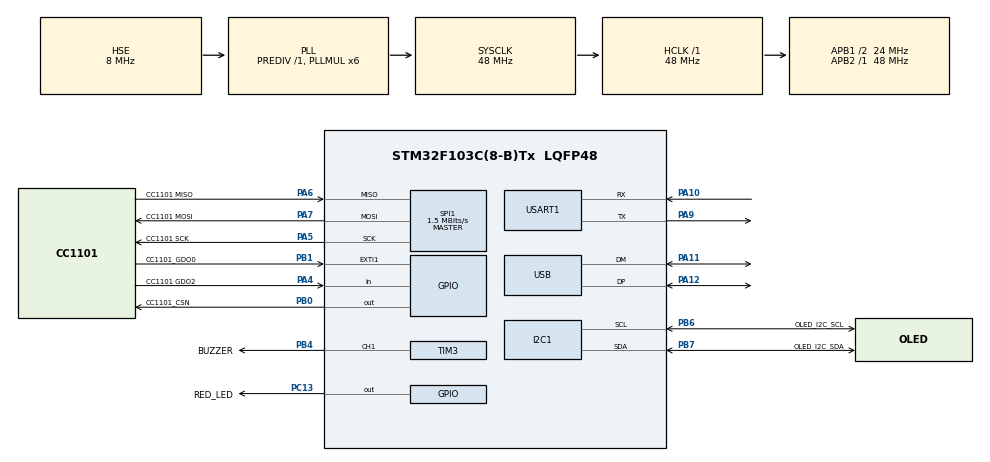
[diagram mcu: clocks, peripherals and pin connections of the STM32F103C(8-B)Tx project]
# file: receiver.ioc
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Dma.I2C1_TX.0.Direction=DMA_MEMORY_TO_PERIPH
Dma.I2C1_TX.0.Instance=DMA1_Channel6
Dma.I2C1_TX.0.MemDataAlignment=DMA_MDATAALIGN_BYTE
Dma.I2C1_TX.0.MemInc=DMA_MINC_ENABLE
Dma.I2C1_TX.0.Mode=DMA_NORMAL
Dma.I2C1_TX.0.PeriphDataAlignment=DMA_PDATAALIGN_BYTE
Dma.I2C1_TX.0.PeriphInc=DMA_PINC_DISABLE
Dma.I2C1_TX.0.Priority=DMA_PRIORITY_LOW
Dma.Request0=I2C1_TX
FREERTOS.INCLUDE_xTaskGetCurrentTaskHandle=1
FREERTOS.Tasks01=defaultTask,0,128,StartDefaultTask,Default,NULL
FREERTOS.configTIMER_QUEUE_LENGTH=10
FREERTOS.configTIMER_TASK_PRIORITY=2
FREERTOS.configTIMER_TASK_STACK_DEPTH=256
FREERTOS.configTOTAL_HEAP_SIZE=8192
FREERTOS.configUSE_IDLE_HOOK=1
FREERTOS.configUSE_TIMERS=1
I2C1.I2C_Mode=I2C_Fast
IWDG.Prescaler=IWDG_PRESCALER_8
Mcu.Family=STM32F1
Mcu.Name=STM32F103C(8-B)Tx
Mcu.Package=LQFP48
NVIC.DMA1_Channel6_IRQn=true\:5\:0\:false\:false\:true\:true\:true
NVIC.EXTI1_IRQn=true\:5\:0\:false\:false\:true\:true\:true
NVIC.I2C1_EV_IRQn=true\:5\:0\:false\:false\:true\:true\:true
NVIC.PriorityGroup=NVIC_PRIORITYGROUP_4
NVIC.TIM1_UP_IRQn=true\:0\:0\:false\:false\:true\:false\:true
NVIC.TimeBase=TIM1_UP_IRQn
NVIC.TimeBaseIP=TIM1
NVIC.USB_LP_CAN1_RX0_IRQn=true\:5\:0\:false\:false\:true\:true\:true
PA10.Mode=Asynchronous
PA10.Signal=USART1_RX
PA11.Mode=Device
PA11.Signal=USB_DM
PA12.Mode=Device
PA12.Signal=USB_DP
PA13.Mode=Serial_Wire
PA13.Signal=SYS_JTMS-SWDIO
PA14.Mode=Serial_Wire
PA14.Signal=SYS_JTCK-SWCLK
PA4.GPIO_Label=CC1101 GDO2
PA4.Signal=GPIO_Input
PA5.GPIO_Label=CC1101 SCK
PA5.Mode=Full_Duplex_Master
PA5.Signal=SPI1_SCK
PA6.GPIO_Label=CC1101 MISO
PA6.Mode=Full_Duplex_Master
PA6.Signal=SPI1_MISO
PA7.GPIO_Label=CC1101 MOSI
PA7.Mode=Full_Duplex_Master
PA7.Signal=SPI1_MOSI
PA9.Mode=Asynchronous
PA9.Signal=USART1_TX
PB0.GPIO_Label=CC1101_CSN
PB0.Signal=GPIO_Output
PB1.GPIO_Label=CC1101_GDO0
PB1.GPIO_ModeDefaultEXTI=GPIO_MODE_IT_FALLING
PB1.GPIO_PuPd=GPIO_NOPULL
PB1.Signal=GPXTI1
PB4.GPIO_Label=BUZZER
PB4.Signal=S_TIM3_CH1
PB6.GPIO_Label=OLED_I2C_SCL
PB6.Mode=I2C
PB6.Signal=I2C1_SCL
PB7.GPIO_Label=OLED_I2C_SDA
PB7.Mode=I2C
PB7.Signal=I2C1_SDA
PC13-TAMPER-RTC.GPIO_Label=RED_LED
PC13-TAMPER-RTC.Signal=GPIO_Output
PD0-OSC_IN.Mode=HSE-External-Oscillator
PD0-OSC_IN.Signal=RCC_OSC_IN
PD1-OSC_OUT.Mode=HSE-External-Oscillator
PD1-OSC_OUT.Signal=RCC_OSC_OUT
ProjectManager.HeapSize=0x200
ProjectManager.StackSize=0x400
ProjectManager.TargetToolchain=Makefile
RCC.ADCPresc=RCC_ADCPCLK2_DIV4
RCC.AHBFreq_Value=48000000
RCC.APB1CLKDivider=RCC_HCLK_DIV2
RCC.APB1Freq_Value=24000000
RCC.APB1TimFreq_Value=48000000
RCC.APB2Freq_Value=48000000
RCC.APB2TimFreq_Value=48000000
RCC.HCLKFreq_Value=48000000
RCC.PLLMUL=RCC_PLL_MUL6
RCC.SYSCLKFreq_VALUE=48000000
RCC.SYSCLKSource=RCC_SYSCLKSOURCE_PLLCLK
RCC.USBFreq_Value=48000000
SH.S_TIM3_CH1.0=TIM3_CH1,PWM Generation1 CH1
SPI1.BaudRatePrescaler=SPI_BAUDRATEPRESCALER_32
SPI1.CalculateBaudRate=1.5 MBits/s
SPI1.Direction=SPI_DIRECTION_2LINES
SPI1.Mode=SPI_MODE_MASTER
SPI1.VirtualType=VM_MASTER
TIM3.AutoReloadPreload=TIM_AUTORELOAD_PRELOAD_ENABLE
TIM3.Channel-PWM\ Generation1\ CH1=TIM_CHANNEL_1
TIM3.OCPolarity_1=TIM_OCPOLARITY_LOW
TIM3.Period=1024
TIM3.Prescaler=32
TIM3.Pulse-PWM\ Generation1\ CH1=512
USART1.VirtualMode=VM_ASYNC
USB_DEVICE.CLASS_NAME_FS=CDC
USB_DEVICE.VirtualMode=Cdc
USB_DEVICE.VirtualModeFS=Cdc_FS
VP_CRC_VS_CRC.Mode=CRC_Activate
VP_FREERTOS_VS_ENABLE.Mode=Enabled
VP_IWDG_VS_IWDG.Mode=IWDG_Activate
VP_SYS_VS_tim1.Mode=TIM1
VP_USB_DEVICE_VS_USB_DEVICE_CDC_FS.Mode=CDC_FS
board=receiver

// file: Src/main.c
/**
  ******************************************************************************
  * @file           : main.c
  * @brief          : Main program body
  ******************************************************************************
  * This notice applies to any and all portions of this file
  * that are not between comment pairs USER CODE BEGIN and
  * USER CODE END. Other portions of this file, whether
  * inserted by the user or by software development tools
  * are owned by their respective copyright owners.
  *
  * Copyright (c) 2018 STMicroelectronics International N.V.
  * All rights reserved.
  *
  * Redistribution and use in source and binary forms, with or without
  * modification, are permitted, provided that the following conditions are met:
  *
  * 1. Redistribution of source code must retain the above copyright notice,
  *    this list of conditions and the following disclaimer.
  * 2. Redistributions in binary form must reproduce the above copyright notice,
  *    this list of conditions and the following disclaimer in the documentation
  *    and/or other materials provided with the distribution.
  * 3. Neither the name of STMicroelectronics nor the names of other
  *    contributors to this software may be used to endorse or promote products
  *    derived from this software without specific written permission.
  * 4. This software, including modifications and/or derivative works of this
  *    software, must execute solely and exclusively on microcontroller or
  *    microprocessor devices manufactured by or for STMicroelectronics.
  * 5. Redistribution and use of this software other than as permitted under
  *    this license is void and will automatically terminate your rights under
  *    this license.
  *
  * THIS SOFTWARE IS PROVIDED BY STMICROELECTRONICS AND CONTRIBUTORS "AS IS"
  * AND ANY EXPRESS, IMPLIED OR STATUTORY WARRANTIES, INCLUDING, BUT NOT
  * LIMITED TO, THE IMPLIED WARRANTIES OF MERCHANTABILITY, FITNESS FOR A
  * PARTICULAR PURPOSE AND NON-INFRINGEMENT OF THIRD PARTY INTELLECTUAL PROPERTY
  * RIGHTS ARE DISCLAIMED TO THE FULLEST EXTENT PERMITTED BY LAW. IN NO EVENT
  * SHALL STMICROELECTRONICS OR CONTRIBUTORS BE LIABLE FOR ANY DIRECT, INDIRECT,
  * INCIDENTAL, SPECIAL, EXEMPLARY, OR CONSEQUENTIAL DAMAGES (INCLUDING, BUT NOT
  * LIMITED TO, PROCUREMENT OF SUBSTITUTE GOODS OR SERVICES; LOSS OF USE, DATA,
  * OR PROFITS; OR BUSINESS INTERRUPTION) HOWEVER CAUSED AND ON ANY THEORY OF
  * LIABILITY, WHETHER IN CONTRACT, STRICT LIABILITY, OR TORT (INCLUDING
  * NEGLIGENCE OR OTHERWISE) ARISING IN ANY WAY OUT OF THE USE OF THIS SOFTWARE,
  * EVEN IF ADVISED OF THE POSSIBILITY OF SUCH DAMAGE.
  *
  ******************************************************************************
  */
#include "main.h"
#include "stm32f1xx_hal.h"
#include "cmsis_os.h"
#include "usb_device.h"

/* USER CODE BEGIN Includes */
#include "usbd_cdc_if.h"
#include "rf/rf.h"
#include "core/core.h"
#include "gui/gui.h"
/* USER CODE END Includes */

CRC_HandleTypeDef hcrc;

I2C_HandleTypeDef hi2c1;
DMA_HandleTypeDef hdma_i2c1_tx;

IWDG_HandleTypeDef hiwdg;

SPI_HandleTypeDef hspi1;

TIM_HandleTypeDef htim3;

UART_HandleTypeDef huart1;

osThreadId defaultTaskHandle;

/* USER CODE BEGIN PV */
/* Private variables ---------------------------------------------------------*/

/* USER CODE END PV */

void SystemClock_Config(void);
static void MX_GPIO_Init(void);
static void MX_DMA_Init(void);
static void MX_CRC_Init(void);
static void MX_IWDG_Init(void);
static void MX_SPI1_Init(void);
static void MX_USART1_UART_Init(void);
static void MX_I2C1_Init(void);
static void MX_TIM3_Init(void);
void StartDefaultTask(void const * argument);

void HAL_TIM_MspPostInit(TIM_HandleTypeDef *htim);

/* USER CODE BEGIN PFP */
/* Private function prototypes -----------------------------------------------*/

/* USER CODE END PFP */

int main(void)
{

  /* MCU Configuration----------------------------------------------------------*/

  /* Reset of all peripherals, Initializes the Flash interface and the Systick. */
  HAL_Init();

  /* Configure the system clock */
  SystemClock_Config();

  /* Initialize all configured peripherals */
  MX_GPIO_Init();
  MX_DMA_Init();
  MX_CRC_Init();
  MX_IWDG_Init();
  MX_SPI1_Init();
  MX_USART1_UART_Init();
  MX_I2C1_Init();
  MX_TIM3_Init();
  /* USER CODE BEGIN 2 */
  rf_init();
  core_init();
  gui_init();
  /* USER CODE END 2 */

  /* Create the thread(s) */
  /* definition and creation of defaultTask */
  osThreadDef(defaultTask, StartDefaultTask, osPriorityNormal, 0, 128);
  defaultTaskHandle = osThreadCreate(osThread(defaultTask), NULL);

  /* Start scheduler */
  osKernelStart();

  /* We should never get here as control is now taken by the scheduler */

  /* Infinite loop */
  while (1)
  {

  }

}

void SystemClock_Config(void)
{

  RCC_OscInitTypeDef RCC_OscInitStruct;
  RCC_ClkInitTypeDef RCC_ClkInitStruct;
  RCC_PeriphCLKInitTypeDef PeriphClkInit;

    /**Initializes the CPU, AHB and APB busses clocks
    */
  RCC_OscInitStruct.OscillatorType = RCC_OSCILLATORTYPE_LSI|RCC_OSCILLATORTYPE_HSE;
  RCC_OscInitStruct.HSEState = RCC_HSE_ON;
  RCC_OscInitStruct.HSEPredivValue = RCC_HSE_PREDIV_DIV1;
  RCC_OscInitStruct.HSIState = RCC_HSI_ON;
  RCC_OscInitStruct.LSIState = RCC_LSI_ON;
  RCC_OscInitStruct.PLL.PLLState = RCC_PLL_ON;
  RCC_OscInitStruct.PLL.PLLSource = RCC_PLLSOURCE_HSE;
  RCC_OscInitStruct.PLL.PLLMUL = RCC_PLL_MUL6;
  if (HAL_RCC_OscConfig(&RCC_OscInitStruct) != HAL_OK)
  {
    _Error_Handler(__FILE__, __LINE__);
  }

    /**Initializes the CPU, AHB and APB busses clocks
    */
  RCC_ClkInitStruct.ClockType = RCC_CLOCKTYPE_HCLK|RCC_CLOCKTYPE_SYSCLK
                              |RCC_CLOCKTYPE_PCLK1|RCC_CLOCKTYPE_PCLK2;
  RCC_ClkInitStruct.SYSCLKSource = RCC_SYSCLKSOURCE_PLLCLK;
  RCC_ClkInitStruct.AHBCLKDivider = RCC_SYSCLK_DIV1;
  RCC_ClkInitStruct.APB1CLKDivider = RCC_HCLK_DIV2;
  RCC_ClkInitStruct.APB2CLKDivider = RCC_HCLK_DIV1;

  if (HAL_RCC_ClockConfig(&RCC_ClkInitStruct, FLASH_LATENCY_1) != HAL_OK)
  {
    _Error_Handler(__FILE__, __LINE__);
  }

  PeriphClkInit.PeriphClockSelection = RCC_PERIPHCLK_USB;
  PeriphClkInit.UsbClockSelection = RCC_USBCLKSOURCE_PLL;
  if (HAL_RCCEx_PeriphCLKConfig(&PeriphClkInit) != HAL_OK)
  {
    _Error_Handler(__FILE__, __LINE__);
  }

    /**Configure the Systick interrupt time
    */
  HAL_SYSTICK_Config(HAL_RCC_GetHCLKFreq()/1000);

    /**Configure the Systick
    */
  HAL_SYSTICK_CLKSourceConfig(SYSTICK_CLKSOURCE_HCLK);

  /* SysTick_IRQn interrupt configuration */
  HAL_NVIC_SetPriority(SysTick_IRQn, 15, 0);
}

/* CRC init function */
static void MX_CRC_Init(void)
{

  hcrc.Instance = CRC;
  if (HAL_CRC_Init(&hcrc) != HAL_OK)
  {
    _Error_Handler(__FILE__, __LINE__);
  }

}

/* I2C1 init function */
static void MX_I2C1_Init(void)
{

  hi2c1.Instance = I2C1;
  hi2c1.Init.ClockSpeed = 400000;
  hi2c1.Init.DutyCycle = I2C_DUTYCYCLE_2;
  hi2c1.Init.OwnAddress1 = 0;
  hi2c1.Init.AddressingMode = I2C_ADDRESSINGMODE_7BIT;
  hi2c1.Init.DualAddressMode = I2C_DUALADDRESS_DISABLE;
  hi2c1.Init.OwnAddress2 = 0;
  hi2c1.Init.GeneralCallMode = I2C_GENERALCALL_DISABLE;
  hi2c1.Init.NoStretchMode = I2C_NOSTRETCH_DISABLE;
  if (HAL_I2C_Init(&hi2c1) != HAL_OK)
  {
    _Error_Handler(__FILE__, __LINE__);
  }

}

/* IWDG init function */
static void MX_IWDG_Init(void)
{

  hiwdg.Instance = IWDG;
  hiwdg.Init.Prescaler = IWDG_PRESCALER_8;
  hiwdg.Init.Reload = 4095;
  if (HAL_IWDG_Init(&hiwdg) != HAL_OK)
  {
    _Error_Handler(__FILE__, __LINE__);
  }

}

/* SPI1 init function */
static void MX_SPI1_Init(void)
{

  /* SPI1 parameter configuration*/
  hspi1.Instance = SPI1;
  hspi1.Init.Mode = SPI_MODE_MASTER;
  hspi1.Init.Direction = SPI_DIRECTION_2LINES;
  hspi1.Init.DataSize = SPI_DATASIZE_8BIT;
  hspi1.Init.CLKPolarity = SPI_POLARITY_LOW;
  hspi1.Init.CLKPhase = SPI_PHASE_1EDGE;
  hspi1.Init.NSS = SPI_NSS_SOFT;
  hspi1.Init.BaudRatePrescaler = SPI_BAUDRATEPRESCALER_32;
  hspi1.Init.FirstBit = SPI_FIRSTBIT_MSB;
  hspi1.Init.TIMode = SPI_TIMODE_DISABLE;
  hspi1.Init.CRCCalculation = SPI_CRCCALCULATION_DISABLE;
  hspi1.Init.CRCPolynomial = 10;
  if (HAL_SPI_Init(&hspi1) != HAL_OK)
  {
    _Error_Handler(__FILE__, __LINE__);
  }

}

/* TIM3 init function */
static void MX_TIM3_Init(void)
{

  TIM_MasterConfigTypeDef sMasterConfig;
  TIM_OC_InitTypeDef sConfigOC;

  htim3.Instance = TIM3;
  htim3.Init.Prescaler = 32;
  htim3.Init.CounterMode = TIM_COUNTERMODE_UP;
  htim3.Init.Period = 1024;
  htim3.Init.ClockDivision = TIM_CLOCKDIVISION_DIV1;
  htim3.Init.AutoReloadPreload = TIM_AUTORELOAD_PRELOAD_ENABLE;
  if (HAL_TIM_PWM_Init(&htim3) != HAL_OK)
  {
    _Error_Handler(__FILE__, __LINE__);
  }

  sMasterConfig.MasterOutputTrigger = TIM_TRGO_RESET;
  sMasterConfig.MasterSlaveMode = TIM_MASTERSLAVEMODE_DISABLE;
  if (HAL_TIMEx_MasterConfigSynchronization(&htim3, &sMasterConfig) != HAL_OK)
  {
    _Error_Handler(__FILE__, __LINE__);
  }

  sConfigOC.OCMode = TIM_OCMODE_PWM1;
  sConfigOC.Pulse = 512;
  sConfigOC.OCPolarity = TIM_OCPOLARITY_LOW;
  sConfigOC.OCFastMode = TIM_OCFAST_DISABLE;
  if (HAL_TIM_PWM_ConfigChannel(&htim3, &sConfigOC, TIM_CHANNEL_1) != HAL_OK)
  {
    _Error_Handler(__FILE__, __LINE__);
  }

  HAL_TIM_MspPostInit(&htim3);

}

/* USART1 init function */
static void MX_USART1_UART_Init(void)
{

  huart1.Instance = USART1;
  huart1.Init.BaudRate = 115200;
  huart1.Init.WordLength = UART_WORDLENGTH_8B;
  huart1.Init.StopBits = UART_STOPBITS_1;
  huart1.Init.Parity = UART_PARITY_NONE;
  huart1.Init.Mode = UART_MODE_TX_RX;
  huart1.Init.HwFlowCtl = UART_HWCONTROL_NONE;
  huart1.Init.OverSampling = UART_OVERSAMPLING_16;
  if (HAL_UART_Init(&huart1) != HAL_OK)
  {
    _Error_Handler(__FILE__, __LINE__);
  }

}

static void MX_DMA_Init(void)
{
  /* DMA controller clock enable */
  __HAL_RCC_DMA1_CLK_ENABLE();

  /* DMA interrupt init */
  /* DMA1_Channel6_IRQn interrupt configuration */
  HAL_NVIC_SetPriority(DMA1_Channel6_IRQn, 5, 0);
  HAL_NVIC_EnableIRQ(DMA1_Channel6_IRQn);

}

/** Configure pins as
        * Analog
        * Input
        * Output
        * EVENT_OUT
        * EXTI
*/
static void MX_GPIO_Init(void)
{

  GPIO_InitTypeDef GPIO_InitStruct;

  /* GPIO Ports Clock Enable */
  __HAL_RCC_GPIOC_CLK_ENABLE();
  __HAL_RCC_GPIOD_CLK_ENABLE();
  __HAL_RCC_GPIOA_CLK_ENABLE();
  __HAL_RCC_GPIOB_CLK_ENABLE();

  /*Configure GPIO pin Output Level */
  HAL_GPIO_WritePin(RED_LED_GPIO_Port, RED_LED_Pin, GPIO_PIN_RESET);

  /*Configure GPIO pin Output Level */
  HAL_GPIO_WritePin(CC1101_CSN_GPIO_Port, CC1101_CSN_Pin, GPIO_PIN_RESET);

  /*Configure GPIO pin : RED_LED_Pin */
  GPIO_InitStruct.Pin = RED_LED_Pin;
  GPIO_InitStruct.Mode = GPIO_MODE_OUTPUT_PP;
  GPIO_InitStruct.Pull = GPIO_NOPULL;
  GPIO_InitStruct.Speed = GPIO_SPEED_FREQ_LOW;
  HAL_GPIO_Init(RED_LED_GPIO_Port, &GPIO_InitStruct);

  /*Configure GPIO pin : CC1101_GDO2_Pin */
  GPIO_InitStruct.Pin = CC1101_GDO2_Pin;
  GPIO_InitStruct.Mode = GPIO_MODE_INPUT;
  GPIO_InitStruct.Pull = GPIO_NOPULL;
  HAL_GPIO_Init(CC1101_GDO2_GPIO_Port, &GPIO_InitStruct);

  /*Configure GPIO pin : CC1101_CSN_Pin */
  GPIO_InitStruct.Pin = CC1101_CSN_Pin;
  GPIO_InitStruct.Mode = GPIO_MODE_OUTPUT_PP;
  GPIO_InitStruct.Pull = GPIO_NOPULL;
  GPIO_InitStruct.Speed = GPIO_SPEED_FREQ_LOW;
  HAL_GPIO_Init(CC1101_CSN_GPIO_Port, &GPIO_InitStruct);

  /*Configure GPIO pin : CC1101_GDO0_Pin */
  GPIO_InitStruct.Pin = CC1101_GDO0_Pin;
  GPIO_InitStruct.Mode = GPIO_MODE_IT_FALLING;
  GPIO_InitStruct.Pull = GPIO_NOPULL;
  HAL_GPIO_Init(CC1101_GDO0_GPIO_Port, &GPIO_InitStruct);

  /* EXTI interrupt init*/
  HAL_NVIC_SetPriority(EXTI1_IRQn, 5, 0);
  HAL_NVIC_EnableIRQ(EXTI1_IRQn);

}

/* USER CODE BEGIN 4 */
void vApplicationIdleHook(void) {
  HAL_IWDG_Refresh(&hiwdg);
}
/* USER CODE END 4 */

void StartDefaultTask(void const * argument)
{
  /* init code for USB_DEVICE */
  MX_USB_DEVICE_Init();

  /* USER CODE BEGIN 5 */

  /* Infinite loop */
  while(true) {
    osDelay(1000);
  }
  /* USER CODE END 5 */
}

void HAL_TIM_PeriodElapsedCallback(TIM_HandleTypeDef *htim)
{
  if (htim->Instance == TIM1) {
    HAL_IncTick();
  }
}

void _Error_Handler(char *file, int line)
{
  /* USER CODE BEGIN Error_Handler_Debug */
  /* User can add his own implementation to report the HAL error return state */
  printf("HAL error in file %s on line %d\n", file, line);
  while(1)
  {
  }
  /* USER CODE END Error_Handler_Debug */
}

#ifdef  USE_FULL_ASSERT
/**
  * @brief  Reports the name of the source file and the source line number
  *         where the assert_param error has occurred.
  * @param  file: pointer to the source file name
  * @param  line: assert_param error line source number
  * @retval None
  */
void assert_failed(uint8_t* file, uint32_t line)
{
  /* USER CODE BEGIN 6 */
  /* User can add his own implementation to report the file name and line number,
    ex: printf("Wrong parameters value: file %s on line %d\r\n", file, line) */
    printf("Assert failed in file %s on line %lu\n", file, line);
  /* USER CODE END 6 */
}
#endif /* USE_FULL_ASSERT */

/************************ (C) COPYRIGHT STMicroelectronics *****END OF FILE****/

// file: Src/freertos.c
/**
  ******************************************************************************
  * File Name          : freertos.c
  * Description        : Code for freertos applications
  ******************************************************************************
  * This notice applies to any and all portions of this file
  * that are not between comment pairs USER CODE BEGIN and
  * USER CODE END. Other portions of this file, whether
  * inserted by the user or by software development tools
  * are owned by their respective copyright owners.
  *
  * Copyright (c) 2017 STMicroelectronics International N.V.
  * All rights reserved.
  *
  * Redistribution and use in source and binary forms, with or without
  * modification, are permitted, provided that the following conditions are met:
  *
  * 1. Redistribution of source code must retain the above copyright notice,
  *    this list of conditions and the following disclaimer.
  * 2. Redistributions in binary form must reproduce the above copyright notice,
  *    this list of conditions and the following disclaimer in the documentation
  *    and/or other materials provided with the distribution.
  * 3. Neither the name of STMicroelectronics nor the names of other
  *    contributors to this software may be used to endorse or promote products
  *    derived from this software without specific written permission.
  * 4. This software, including modifications and/or derivative works of this
  *    software, must execute solely and exclusively on microcontroller or
  *    microprocessor devices manufactured by or for STMicroelectronics.
  * 5. Redistribution and use of this software other than as permitted under
  *    this license is void and will automatically terminate your rights under
  *    this license.
  *
  * THIS SOFTWARE IS PROVIDED BY STMICROELECTRONICS AND CONTRIBUTORS "AS IS"
  * AND ANY EXPRESS, IMPLIED OR STATUTORY WARRANTIES, INCLUDING, BUT NOT
  * LIMITED TO, THE IMPLIED WARRANTIES OF MERCHANTABILITY, FITNESS FOR A
  * PARTICULAR PURPOSE AND NON-INFRINGEMENT OF THIRD PARTY INTELLECTUAL PROPERTY
  * RIGHTS ARE DISCLAIMED TO THE FULLEST EXTENT PERMITTED BY LAW. IN NO EVENT
  * SHALL STMICROELECTRONICS OR CONTRIBUTORS BE LIABLE FOR ANY DIRECT, INDIRECT,
  * INCIDENTAL, SPECIAL, EXEMPLARY, OR CONSEQUENTIAL DAMAGES (INCLUDING, BUT NOT
  * LIMITED TO, PROCUREMENT OF SUBSTITUTE GOODS OR SERVICES; LOSS OF USE, DATA,
  * OR PROFITS; OR BUSINESS INTERRUPTION) HOWEVER CAUSED AND ON ANY THEORY OF
  * LIABILITY, WHETHER IN CONTRACT, STRICT LIABILITY, OR TORT (INCLUDING
  * NEGLIGENCE OR OTHERWISE) ARISING IN ANY WAY OUT OF THE USE OF THIS SOFTWARE,
  * EVEN IF ADVISED OF THE POSSIBILITY OF SUCH DAMAGE.
  *
  ******************************************************************************
  */

#include "FreeRTOS.h"
#include "task.h"

/* USER CODE BEGIN Includes */
#include "stm32f1xx_hal.h"
/* USER CODE END Includes */

/* Hook prototypes */
void vApplicationIdleHook(void);

/* USER CODE BEGIN 2 */
__weak void vApplicationIdleHook( void )
{
   /* vApplicationIdleHook() will only be called if configUSE_IDLE_HOOK is set
   to 1 in FreeRTOSConfig.h. It will be called on each iteration of the idle
   task. It is essential that code added to this hook function never attempts
   to block in any way (for example, call xQueueReceive() with a block time
   specified, or call vTaskDelay()). If the application makes use of the
   vTaskDelete() API function (as this demo application does) then it is also
   important that vApplicationIdleHook() is permitted to return to its calling
   function, because it is the responsibility of the idle task to clean up
   memory allocated by the kernel to any task that has since been deleted. */
}
/* USER CODE END 2 */

/************************ (C) COPYRIGHT STMicroelectronics *****END OF FILE****/
